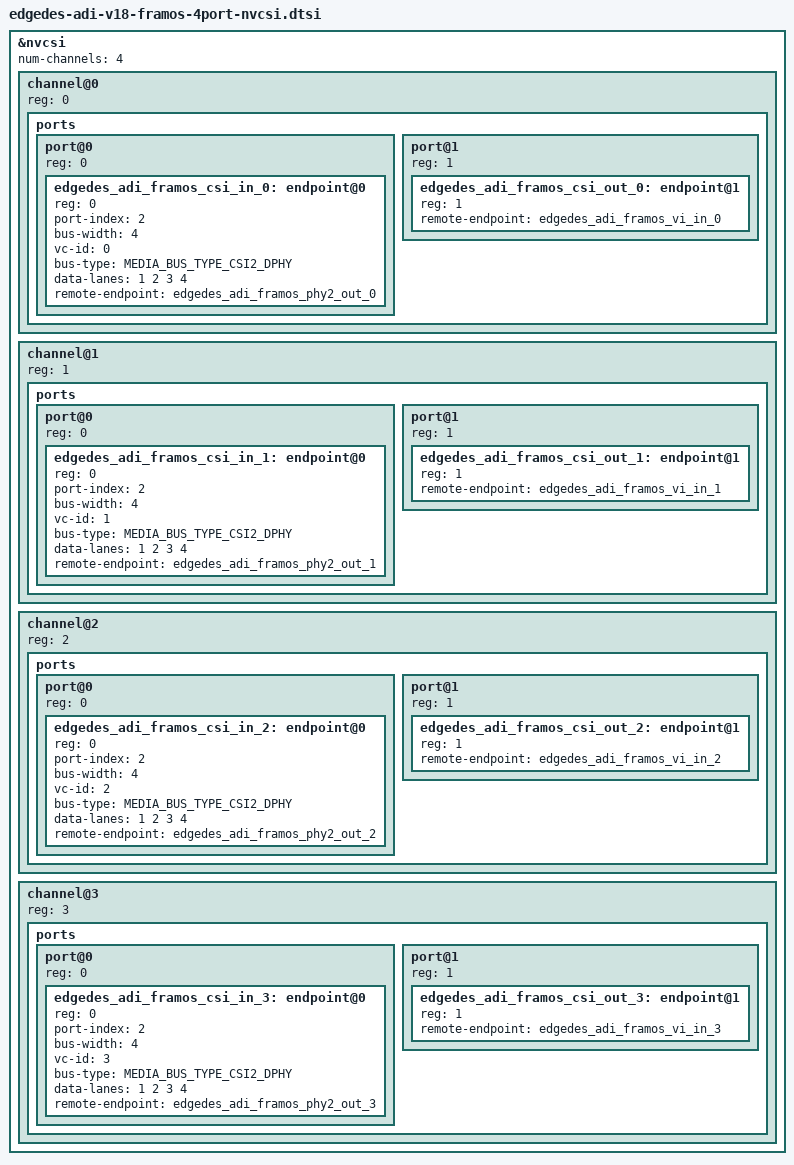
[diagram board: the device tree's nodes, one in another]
// SPDX-License-Identifier: GPL-2.0-only
// SPDX-FileCopyrightText: Copyright (c) 2026 CompuLab Ltd.

fragment@5 {
	target = <&nvcsi>;
	__overlay__ {
		status = "okay";
		num-channels = <4>;
		#address-cells = <1>;
		#size-cells = <0>;
		channel@0 {
			reg = <0>;
			ports {
				#address-cells = <1>;
				#size-cells = <0>;
				port@0 {
					reg = <0>;
					#address-cells = <1>;
					#size-cells = <0>;
					edgedes_adi_framos_csi_in_0: endpoint@0 {
						reg = <0>;
						port-index = <2>;
						bus-width = <4>;
						vc-id = <0>;
						bus-type = <MEDIA_BUS_TYPE_CSI2_DPHY>;
						data-lanes = <1 2 3 4>;
						remote-endpoint = <&edgedes_adi_framos_phy2_out_0>;
					};
				};
				port@1 {
					reg = <1>;
					#address-cells = <1>;
					#size-cells = <0>;
					edgedes_adi_framos_csi_out_0: endpoint@1 {
						reg = <1>;
						remote-endpoint = <&edgedes_adi_framos_vi_in_0>;
					};
				};
			};
		};
		channel@1 {
			reg = <1>;
			ports {
				#address-cells = <1>;
				#size-cells = <0>;
				port@0 {
					reg = <0>;
					#address-cells = <1>;
					#size-cells = <0>;
					edgedes_adi_framos_csi_in_1: endpoint@0 {
						reg = <0>;
						port-index = <2>;
						bus-width = <4>;
						vc-id = <1>;
						bus-type = <MEDIA_BUS_TYPE_CSI2_DPHY>;
						data-lanes = <1 2 3 4>;
						remote-endpoint = <&edgedes_adi_framos_phy2_out_1>;
					};
				};
				port@1 {
					reg = <1>;
					#address-cells = <1>;
					#size-cells = <0>;
					edgedes_adi_framos_csi_out_1: endpoint@1 {
						reg = <1>;
						remote-endpoint = <&edgedes_adi_framos_vi_in_1>;
					};
				};
			};
		};
		channel@2 {
			reg = <2>;
			ports {
				#address-cells = <1>;
				#size-cells = <0>;
				port@0 {
					reg = <0>;
					#address-cells = <1>;
					#size-cells = <0>;
					edgedes_adi_framos_csi_in_2: endpoint@0 {
						reg = <0>;
						port-index = <2>;
						bus-width = <4>;
						vc-id = <2>;
						bus-type = <MEDIA_BUS_TYPE_CSI2_DPHY>;
						data-lanes = <1 2 3 4>;
						remote-endpoint = <&edgedes_adi_framos_phy2_out_2>;
					};
				};
				port@1 {
					reg = <1>;
					#address-cells = <1>;
					#size-cells = <0>;
					edgedes_adi_framos_csi_out_2: endpoint@1 {
						reg = <1>;
						remote-endpoint = <&edgedes_adi_framos_vi_in_2>;
					};
				};
			};
		};
		channel@3 {
			reg = <3>;
			ports {
				#address-cells = <1>;
				#size-cells = <0>;
				port@0 {
					reg = <0>;
					#address-cells = <1>;
					#size-cells = <0>;
					edgedes_adi_framos_csi_in_3: endpoint@0 {
						reg = <0>;
						port-index = <2>;
						bus-width = <4>;
						vc-id = <3>;
						bus-type = <MEDIA_BUS_TYPE_CSI2_DPHY>;
						data-lanes = <1 2 3 4>;
						remote-endpoint = <&edgedes_adi_framos_phy2_out_3>;
					};
				};
				port@1 {
					reg = <1>;
					#address-cells = <1>;
					#size-cells = <0>;
					edgedes_adi_framos_csi_out_3: endpoint@1 {
						reg = <1>;
						remote-endpoint = <&edgedes_adi_framos_vi_in_3>;
					};
				};
			};
		};
	};
};
